# M051AN_v1 register map
File version: 1.0
Registers are 32-bit, read-write, reset 0x0 unless marked. A register's access mark holds for its fields unless they carry their own. Offsets are from the block's base; [hi:lo] are bit positions; 'fields as' and 'values as' point back to an identical list.

## TMR23 — TIMER Register Map
Base 0x40110000
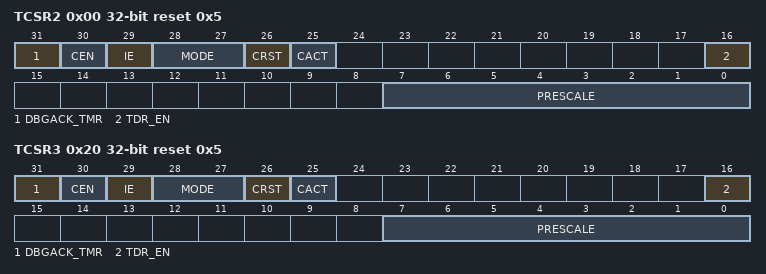
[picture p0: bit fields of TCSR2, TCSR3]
0x00 TCSR2 reset 0x5 — Timer2 Control and Status Register
  [31] DBGACK_TMR — ICE debug mode acknowledge Disable (write-protected). TIMER counter will be held while ICE debug mode acknowledged.
    0=ICE debug mode acknowledgement effects TIMER counting; 1=ICE debug mode acknowledgement disabled
  [30] CEN — Timer Enable Bit
    0=Stops/Suspends counting; 1=Starts counting
  [29] IE — Interrupt Enable Bit. If timer interrupt is enabled, the timer asserts its interrupt signal when the associated timer is equal to TCMPR.
    0=Disable timer Interrupt; 1=Enable timer Interrupt
  [28:27] MODE — Timer Operating Mode
  [26] CRST — Timer Reset Bit. Set this bit will reset the 24-bit up-timer, 8-bit pre-scale counter and also force CEN to 0.
    0=No effect; 1=Reset Timer's 8-bit pre-scale counter, internal 24-bit up-timer and CEN bit
  [25] CACT ro — Timer Active Status Bit (Read only). This bit indicates the status of timer.
    0=Timer is not active; 1=Timer is active
  [16] TDR_EN — Data Load Enable. When TDR_EN is set, TDR (Timer Data Register) will be updated continuously with the 24-bit up-timer value.
    0=Timer Data Register update disable; 1=Timer Data Register update enable
  [7:0] PRESCALE — Pre-scale Counter
0x04 TCMPR2 — Timer2 Compare Register
  [23:0] TCMP — Timer Compared Value. Note1: Never write 0x0 or 0x1 in TCMP, or the core will run into unknown state. Note2: When timer is operating at continuous counting mode, the 24-bit up-timer will count continuously if software writes a new value into TCMP. If timer is operating at other modes, the 24-bit up-timer will restart counting and using newest TCMP value to be the compared value if software writes a new value into TCMP.
0x08 TISR2 — Timer2 Interrupt Status Register
  [0] TIF — Timer Interrupt Flag. This bit indicates the interrupt status of Timer. TIF bit is set by hardware when the up counting value of internal 24-bit timer matches the timer compared value (TCMP). It is cleared by writing 1 to this bit.
0x0C TDR2 ro — Timer2 Data Register
  [23:0] TDR — Timer Data Register. When TCSR.TDR_EN is set to 1, the internal 24-bit up-timer value will be loaded into TDR. User can read this register for the up-timer value.
0x20 TCSR3 reset 0x5 — Timer3 Control and Status Register
  fields as TCSR2
0x24 TCMPR3 — Timer3 Compare Register
  fields as TCMPR2
0x28 TISR3 — Timer3 Interrupt Status Register
  fields as TISR2
0x2C TDR3 ro — Timer3 Data Register
  fields as TDR2

## WDT — WDT Register Map
Base 0x40004000
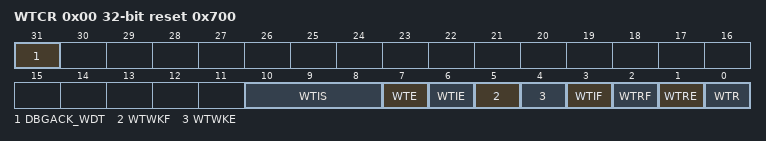
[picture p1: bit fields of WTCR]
0x00 WTCR reset 0x700 — Watchdog Timer Control Register
  [31] DBGACK_WDT — ICE debug mode acknowledge Disable (write-protected). Watchdog Timer counter will keep going no matter ICE debug mode acknowledged or not.
    0=ICE debug mode acknowledgement effects Watchdog Timer counting; 1=ICE debug mode acknowledgement disabled
  [10:8] WTIS — Watchdog Timer Interval Select (write protection bits)
  [7] WTE — Watchdog Timer Enable (write protection bits)
    0=Disable the Watchdog timer (This action will reset the internal counter); 1=Enable the Watchdog timer
  [6] WTIE — Watchdog Timer Interrupt Enable (write protection bits)
    0=Disable the Watchdog timer interrupt; 1=Enable the Watchdog timer interrupt
  [5] WTWKF — Watchdog Timer Wake-up Flag. If Watchdog timer causes chip wakes up from power down mode, this bit will be set to high. It must be cleared by software with a write 1 to this bit.
    0=Watchdog timer does not cause chip wake-up; 1=Chip wake-up from idle or power down mode by Watchdog timeout
  [4] WTWKE — Watchdog Timer Wake-up Function Enable bit (write-protection bit). Note: Chip can wake-up by WDT only if WDT clock source select RC10K
    0=Disable Watchdog timer wake-up chip function; 1=Enable the Wake-up function that Watchdog timer timeout can wake-up chip from power down mode
  [3] WTIF — Watchdog Timer Interrupt Flag. If the Watchdog timer interrupt is enabled, then the hardware will set this bit to indicate that the Watchdog timer interrupt has occurred. Note: This bit is cleared by writing 1 to this bit.
    0=Watchdog timer interrupt did not occur; 1=Watchdog timer interrupt occurs
  [2] WTRF — Watchdog Timer Reset Flag. When the Watchdog timer initiates a reset, the hardware will set this bit. This flag can be read by software to determine the source of reset. Software is responsible to clear it manually by writing 1 to it. If WTRE is disabled, then the Watchdog timer has no effect on this bit. Note: Write 1 to clear this bit to zero.
    0=Watchdog timer reset did not occur; 1=Watchdog timer reset occurs
  [1] WTRE — Watchdog Timer Reset Enable. Setting this bit will enable the Watchdog timer reset function.
    0=Disable Watchdog timer reset function; 1=Enable Watchdog timer reset function
  [0] WTR — Clear Watchdog Timer (write-protection bit). Set this bit will clear the Watchdog timer. Note: This bit will auto clear after few clock cycle
    0=Writing 0 to this bit has no effect; 1=Reset the contents of the Watchdog timer
